# STM32F303xE register map
File version: 1.0
Registers are 32-bit, read-write, reset 0x0 unless marked. A register's access mark holds for its fields unless they carry their own. Offsets are from the block's base; [hi:lo] are bit positions; {n}, {i} and the like mark numbered series; 'fields as' and 'values as' point back to an identical list.

## OPAMP1 — Operational Amplifier (OPAMP)
Base 0x40010038; alternate view of OPAMP
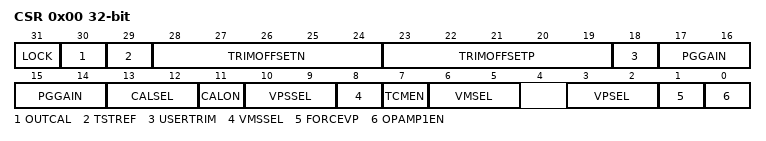
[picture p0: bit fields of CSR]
0x00 CSR — OPAMP control and status register
  [31] LOCK — OPAMP lock
  [30] OUTCAL — OPAMP output status flag
  [29] TSTREF — It enables the switch to put out the internal reference
  [28:24] TRIMOFFSETN — Offset trimming value (NMOS)
  [23:19] TRIMOFFSETP — Offset trimming value (PMOS)
  [18] USERTRIM — User trimming enable
  [17:14] PGGAIN — Gain in PGA mode
  [13:12] CALSEL — Calibration selection
  [11] CALON — Calibration mode enable
  [10:9] VPSSEL — Non inverting input secondary selection
  [8] VMSSEL — Inverting input secondary selection
  [7] TCMEN — Timer-Controlled Mux mode enable
  [6:5] VMSEL — Inverting input selection
  [3:2] VPSEL — Non inverting input selection
  [1] FORCEVP — Connect the internal references to the plus input of the OPAMPX
  [0] OPAMP1EN — OPAMP1 enable

## OPAMP2 — Operational Amplifier (OPAMP)
Base 0x4001003C
Registers as OPAMP1 (with OPAMP1 read as OPAMP2).

## OPAMP3 — Operational Amplifier (OPAMP)
Base 0x40010040
Registers as OPAMP1 (with OPAMP1 read as OPAMP3).

## OPAMP4 — Operational Amplifier (OPAMP)
Base 0x40010044
Registers as OPAMP1 (with OPAMP1 read as OPAMP4).

## EXTI — External Interrupt/Event Controller
Base 0x40010400
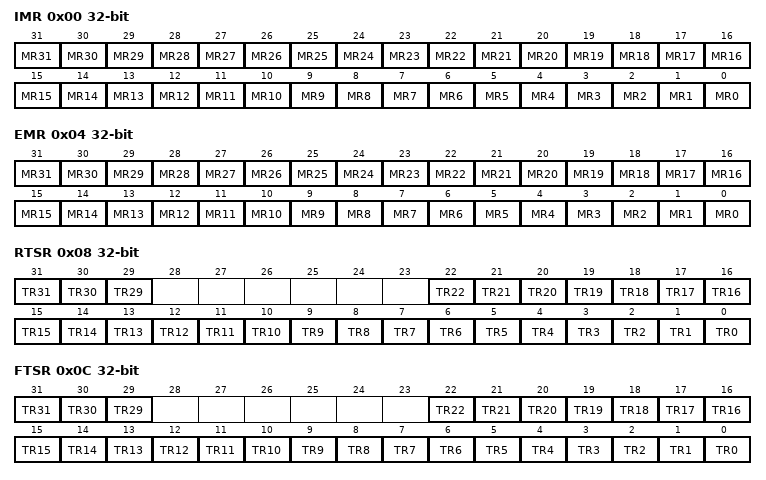
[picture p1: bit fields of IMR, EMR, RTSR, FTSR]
0x00 IMR — EXTI Interrupt mask register
  [n] MR{n} (n=0..31) — Interrupt Mask on line {n}
0x04 EMR — EXTI Event mask register
  [n] MR{n} (n=0..31) — Event Mask on line {n}
0x08 RTSR — EXTI Rising trigger selection register
  [31] TR31 — Rising trigger event configuration bit of line 31
  [30] TR30 — Rising trigger event configuration bit of line 30
  [29] TR29 — Rising trigger event configuration bit of line 29
  [n] TR{n} (n=0..22) — Rising trigger event configuration bit of line {n}
0x0C FTSR — EXTI Falling trigger selection register
  [31] TR31 — Falling trigger event configuration bit of line 31
  [30] TR30 — Falling trigger event configuration bit of line 30
  [29] TR29 — Falling trigger event configuration bit of line 29
  [n] TR{n} (n=0..22) — Falling trigger event configuration bit of line {n}
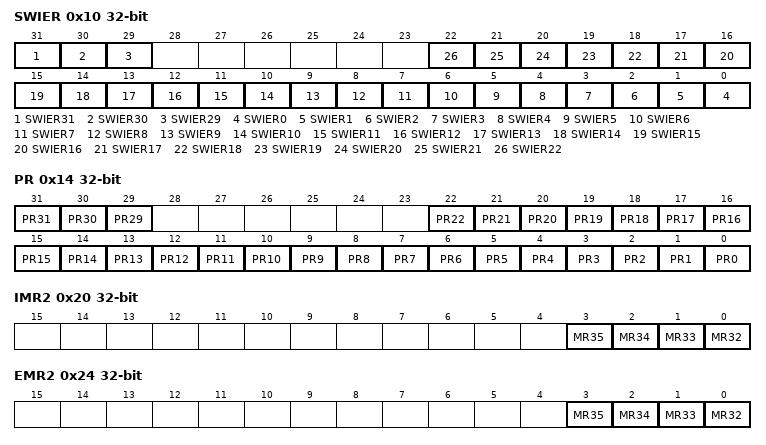
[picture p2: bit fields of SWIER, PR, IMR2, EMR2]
0x10 SWIER — EXTI Software interrupt event register
  [31] SWIER31 — Software Interrupt on line 31
  [30] SWIER30 — Software Interrupt on line 30
  [29] SWIER29 — Software Interrupt on line 29
  [n] SWIER{n} (n=0..22) — Software Interrupt on line {n}
0x14 PR — EXTI Pending register
  [31] PR31 — Pending bit for line 31
  [30] PR30 — Pending bit for line 30
  [29] PR29 — Pending bit for line 29
  [n] PR{n} (n=0..22) — Pending bit for line {n}
0x20 IMR2 — EXTI Interrupt mask register
  [n-32] MR{n} (n=32..35) — Interrupt Mask on line {n}
0x20 IMR2_ALT (alternate view of IMR2) — EXTI Interrupt mask register
  [3:0] IM
0x24 EMR2 — EXTI Event mask register
  [3] MR35 — Event Mask on line 34
  [2] MR34 — Event Mask on line 34
  [1] MR33 — Event Mask on line 33
  [0] MR32 — Event Mask on line 32
0x24 EMR2_ALT (alternate view of EMR2) — EXTI Event mask register
  [3:0] EM
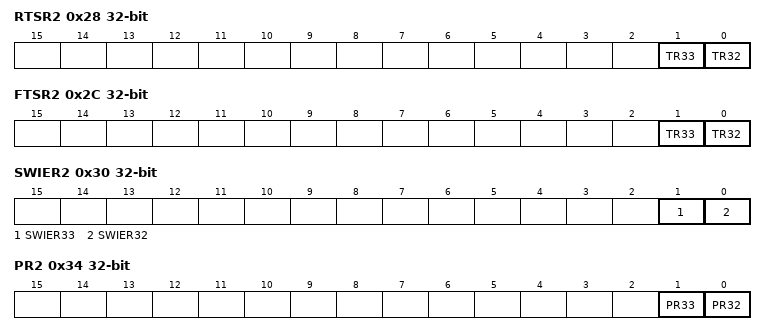
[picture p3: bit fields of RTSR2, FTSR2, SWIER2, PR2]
0x28 RTSR2 — EXTI Rising trigger selection register
  [1] TR33 — Rising trigger event configuration bit of line 33
  [0] TR32 — Rising trigger event configuration bit of line 32
0x2C FTSR2 — EXTI Falling trigger selection register
  [1] TR33 — Falling trigger event configuration bit of line 33
  [0] TR32 — Falling trigger event configuration bit of line 32
0x30 SWIER2 — EXTI Software interrupt event register
  [1] SWIER33 — Software Interrupt on line 33
  [0] SWIER32 — Software Interrupt on line 32
0x34 PR2 — EXTI Pending register
  [1] PR33 — Pending bit for line 33
  [0] PR32 — Pending bit for line 32

## DMA1
Base 0x40020000
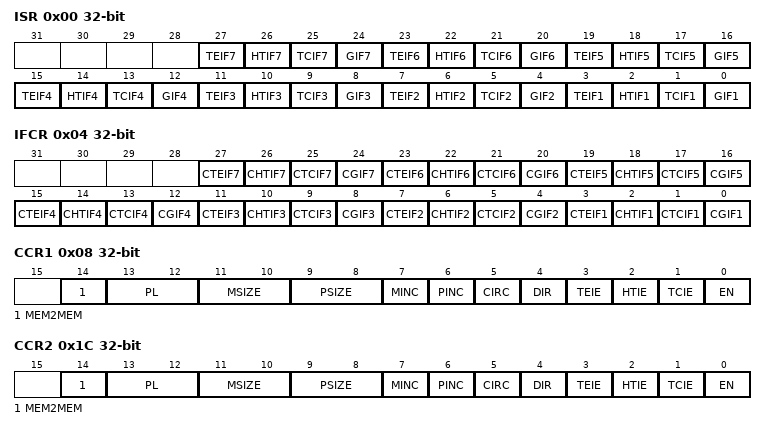
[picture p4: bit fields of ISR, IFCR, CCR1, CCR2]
0x00 ISR — DMA interrupt status register
  [4n-1] TEIF{n} (n=1..7) — Channel {n} Transfer Error flag
  [4n-2] HTIF{n} (n=1..7) — Channel {n} Half Transfer flag
  [4n-3] TCIF{n} (n=1..7) — Channel {n} Transfer Complete flag
  [4n-4] GIF{n} (n=1..7) — Channel {n} Global interrupt flag
0x04 IFCR — DMA interrupt flag clear register
  [4n-1] CTEIF{n} (n=1..7) — Channel {n} Transfer Error clear
  [4n-2] CHTIF{n} (n=1..7) — Channel {n} Half Transfer clear
  [4n-3] CTCIF{n} (n=1..7) — Channel {n} Transfer Complete clear
  [4n-4] CGIF{n} (n=1..7) — Channel {n} Global interrupt clear
0x08 CCR1 — DMA channel x configuration register
  [14] MEM2MEM — Memory to memory mode
  [13:12] PL — PL[1:0] bits(Channel Priority level)
  [11:10] MSIZE — MSIZE[1:0] bits (Memory size)
  [9:8] PSIZE — PSIZE[1:0] bits (Peripheral size)
  [7] MINC — Memory increment mode
  [6] PINC — Peripheral increment mode
  [5] CIRC — Circular mode
  [4] DIR — Data transfer direction
  [3] TEIE — Transfer error interrupt enable
  [2] HTIE — Half Transfer interrupt enable
  [1] TCIE — Transfer complete interrupt enable
  [0] EN — Channel enable
0x0C CNDTR1 — DMA channel x number of data register
  [15:0] NDT — Number of data to Transfer
0x10 CPAR1 — DMA channel x peripheral address register
  [31:0] PA — Peripheral Address
{0x0+0x14*i} CMAR{i} (i=1..7) — DMA channel x memory address register
  [31:0] MA — Memory Address
0x1C CCR2 — DMA channel x configuration register
  fields as CCR1
0x20 CNDTR2 — DMA channel x number of data register
  [15:0] NDT — Number of data to Transfer
0x24 CPAR2 — DMA channel x peripheral address register
  [31:0] PA — Peripheral Address
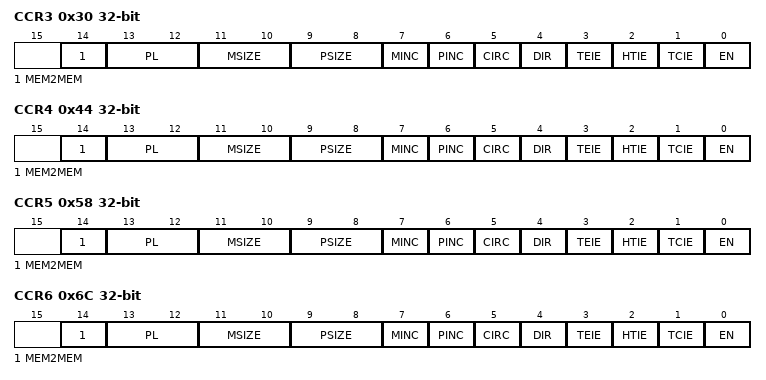
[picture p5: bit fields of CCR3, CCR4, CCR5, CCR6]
0x30 CCR3 — DMA channel x configuration register
  fields as CCR1
0x34 CNDTR3 — DMA channel x number of data register
  [15:0] NDT — Number of data to Transfer
0x38 CPAR3 — DMA channel x peripheral address register
  [31:0] PA — Peripheral Address
0x44 CCR4 — DMA channel x configuration register
  fields as CCR1
0x48 CNDTR4 — DMA channel x number of data register
  [15:0] NDT — Number of data to Transfer
0x4C CPAR4 — DMA channel x peripheral address register
  [31:0] PA — Peripheral Address
0x58 CCR5 — DMA channel x configuration register
  fields as CCR1
0x5C CNDTR5 — DMA channel x number of data register
  [15:0] NDT — Number of data to Transfer
0x60 CPAR5 — DMA channel x peripheral address register
  [31:0] PA — Peripheral Address
0x6C CCR6 — DMA channel x configuration register
  fields as CCR1
0x70 CNDTR6 — DMA channel x number of data register
  [15:0] NDT — Number of data to Transfer
0x74 CPAR6 — DMA channel x peripheral address register
  [31:0] PA — Peripheral Address
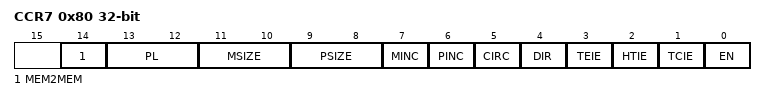
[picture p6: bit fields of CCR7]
0x80 CCR7 — DMA channel x configuration register
  fields as CCR1
0x84 CNDTR7 — DMA channel x number of data register
  [15:0] NDT — Number of data to Transfer
0x88 CPAR7 — DMA channel x peripheral address register
  [31:0] PA — Peripheral Address

## DMA2
Base 0x40020400
Registers as DMA1, without CCR6, CNDTR6, CPAR6, CMAR6, CCR7, CNDTR7, CPAR7, CMAR7.
